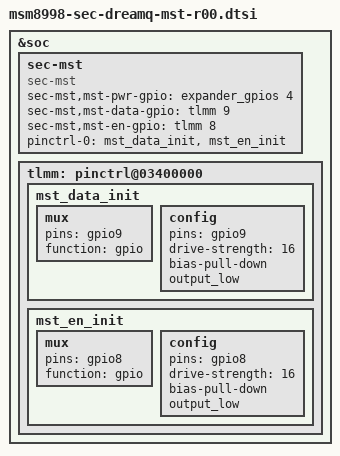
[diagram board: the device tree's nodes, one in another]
/* Copyright (c) 2013, Samsung Electronics Corporation. All rights reserved.
 *
 * This program is free software; you can redistribute it and/or modify
 * it under the terms of the GNU General Public License version 2 and
 * only version 2 as published by the Free Software Foundation.
 *
 * This program is distributed in the hope that it will be useful,
 * but WITHOUT ANY WARRANTY; without even the implied warranty of
 * MERCHANTABILITY or FITNESS FOR A PARTICULAR PURPOSE.  See the
 * GNU General Public License for more details.
 */

&soc {
	sec-mst {
		compatible = "sec-mst";
		sec-mst,mst-pwr-gpio = <&expander_gpios 4 0>;
		sec-mst,mst-data-gpio = <&tlmm 9 0>;
		sec-mst,mst-en-gpio = <&tlmm 8 0>;
		//sec-mst,mst-vdd = "s2mpb02-ldo17";

		pinctrl-names = "mst_active";
		pinctrl-0 = <&mst_data_init &mst_en_init>;
	};

	tlmm: pinctrl@03400000 {
		mst_data_init: mst_data_init {
			mux {
				pins = "gpio9";
				function = "gpio";
			};
			config {
				pins = "gpio9";
				drive-strength = <16>;
				bias-pull-down;
				output_low;
			};
		};
		mst_en_init: mst_en_init {
			mux {
				pins = "gpio8";
				function = "gpio";
			};
			config {
				pins = "gpio8";
				drive-strength = <16>;
				bias-pull-down;
				output_low;
			};
		};
	};
};
	
